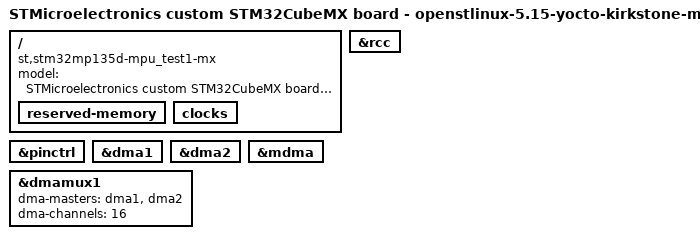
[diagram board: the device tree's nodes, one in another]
/* SPDX-License-Identifier: (GPL-2.0+ OR BSD-3-Clause) */
/*
 * Copyright (C) STMicroelectronics 2023 - All Rights Reserved
 * Author: STM32CubeMX code generation for STMicroelectronics.
 */

/* For more information on Device Tree configuration, please refer to
 * https://wiki.st.com/stm32mpu/wiki/Category:Device_tree_configuration
 */

/dts-v1/;
#include <dt-bindings/pinctrl/stm32-pinfunc.h>

#include "stm32mp135.dtsi"
#include "stm32mp13xd.dtsi"

/* USER CODE BEGIN includes */
/* USER CODE END includes */

/ {
	model = "STMicroelectronics custom STM32CubeMX board - openstlinux-5.15-yocto-kirkstone-mp1-v22.11.23";
	compatible = "st,stm32mp135d-mpu_test1-mx", "st,stm32mp135";

	/* !!! log : Warning - no DDR config found: 'memory' node not generated  !!! */

	/*
	memory@??? {
		reg = < ??? >;
	};
	*/

	reserved-memory {
		#address-cells = <1>;
		#size-cells = <1>;
		ranges;

		/* USER CODE BEGIN reserved-memory */
		/* USER CODE END reserved-memory */
	};

	/* USER CODE BEGIN root */
	/* USER CODE END root */

	clocks {

		/* USER CODE BEGIN clocks */
		/* USER CODE END clocks */
	};

}; /*root*/

&pinctrl {

	/* USER CODE BEGIN pinctrl */
	/* USER CODE END pinctrl */
};

&dma1{
	status = "okay";

	/* USER CODE BEGIN dma1 */
	/* USER CODE END dma1 */
};

&dma2{
	status = "okay";

	/* USER CODE BEGIN dma2 */
	/* USER CODE END dma2 */
};

&dmamux1{
	status = "okay";

	dma-masters = <&dma1 &dma2>;
	dma-channels = <16>;

	/* USER CODE BEGIN dmamux1 */
	/* USER CODE END dmamux1 */
};

&mdma{
	status = "okay";

	/* USER CODE BEGIN mdma */
	/* USER CODE END mdma */
};

&rcc{
	status = "okay";

	/* USER CODE BEGIN rcc */
	/* USER CODE END rcc */
};

/* USER CODE BEGIN addons */
/* USER CODE END addons */

